# ASR6601 register map
Vendor: ASR Microelectronics; Series: ASR6601; File version: 1
CPU: CM4 r0p1, little endian, no MPU, FPU, 3 interrupt priority bits
Registers are 32-bit, read-write, reset 0x0 unless marked. A register's access mark holds for its fields unless they carry their own. Offsets are from the block's base; [hi:lo] are bit positions; {n}, {i} and the like mark numbered series.

## RCC — Reset and clock control
Base 0x40000000
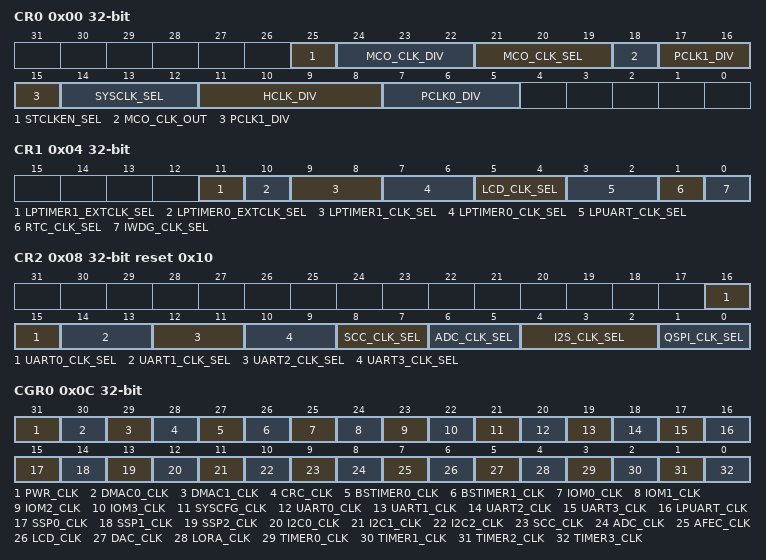
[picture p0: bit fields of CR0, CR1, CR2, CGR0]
0x00 CR0 — Clock control register 0
  [25] STCLKEN_SEL — SYSTICK clock source selection
    0=XO32K (XO32K is SYSTICK clock source); 1=RCO32K (RCO32K is SYSTICK clock source)
  [24:22] MCO_CLK_DIV — MCO clock source prescaler
    0=MCO clock source is used directly; 4=MCO clock source is divided by 2; 5=MCO clock source is divided by 4; 6=MCO clock source is divided by 8; 7=MCO clock source is divided by 16
  [21:19] MCO_CLK_SEL — MCO clock source selection
    0=RCO32K (RCO32K is MCO clock source); 1=XO32K (XO32K is MCO clock source); 2=RCO4M (RCO4M is MCO clock source); 3=XO24M (XO24M is MCO clock source); 4=XO32M (XO32M is MCO clock source); 5=RCO48M (RCO48M is MCO clock source); 6=PLL (PLL is MCO clock source); 7=SYSCLCK (SYSCLCK is MCO clock source)
  [18] MCO_CLK_OUT — MCO clock output
    0=DIS (MCO clock output disable); 1=EN (MCO clock output enable)
  [17:15] PCLK1_DIV — PCLK1 clock source prescaler
    0=PCLK1 clock source is used directly; 1=PCLK1 clock source is divided by 2; 2=PCLK1 clock source is divided by 4; 3=PCLK1 clock source is divided by 8; 4=PCLK1 clock source is divided by 16
  [14:12] SYSCLK_SEL — SYSCLK clock source selection
    0=RCO48M_DIV2 (RCO48M / 2 is SYSCLK clock source); 1=RCO32K (RCO32K is SYSCLK clock source); 2=XO32K (XO32K is SYSCLK clock source); 3=PLL (PLL is SYSCLK clock source); 4=XO24M (XO24M is SYSCLK clock source); 5=XO32M (XO32M is SYSCLK clock source); 6=RCO4M (RCO4M is SYSCLK clock source); 7=RCO48M (RCO48M is SYSCLK clock source)
  [11:8] HCLK_DIV — HCLK clock source prescaler
    0=HCLK clock source is used directly; 1=HCLK clock source is divided by 2; 2=HCLK clock source is divided by 4; 3=HCLK clock source is divided by 8; 4=HCLK clock source is divided by 16; 5=HCLK clock source is divided by 32; 6=HCLK clock source is divided by 64; 7=HCLK clock source is divided by 128; 8=HCLK clock source is divided by 256; 9=HCLK clock source is divided by 512
  [7:5] PCLK0_DIV — PCLK0 clock source prescaler
    0=PCLK0 clock source is used directly; 1=PCLK0 clock source is divided by 2; 2=PCLK0 clock source is divided by 4; 3=PCLK0 clock source is divided by 8; 4=PCLK0 clock source is divided by 16
0x04 CR1 — Clock control register 1
  [11] LPTIMER1_EXTCLK_SEL — LPTIMER1 external clock source enable
    0=DIS (LPTIMER1 external clock source disable); 1=EN (LPTIMER1 external clock source enable)
  [10] LPTIMER0_EXTCLK_SEL — LPTIMER0 external clock source enable
    0=DIS (LPTIMER0 external clock source disable); 1=EN (LPTIMER0 external clock source enable)
  [9:8] LPTIMER1_CLK_SEL — LPTIMER1 clock source selection
    0=PCLK0 (PCLK0 is LPTIMER1 clock source); 1=RCO4M (RCO4M is LPTIMER1 clock source); 2=XO32K (XO32K is LPTIMER1 clock source); 3=RCO32K (RCO32K is LPTIMER1 clock source)
  [7:6] LPTIMER0_CLK_SEL — LPTIMER0 clock source selection
    0=PCLK0 (PCLK0 is LPTIMER0 clock source); 1=RCO4M (RCO4M is LPTIMER0 clock source); 2=XO32K (XO32K is LPTIMER0 clock source); 3=RCO32K (RCO32K is LPTIMER0 clock source)
  [5:4] LCD_CLK_SEL — LCD clock source selection
    0=XO32K (XO32K is LCD clock source); 1=RCO32K (RCO32K is LCD clock source); 2=RCO4M (RCO4M is LCD clock source)
  [3:2] LPUART_CLK_SEL — LPUART clock source selection
    0=XO32K (XO32K is LPUART clock source); 1=RCO32K (RCO32K is LPUART clock source); 2=RCO4M (RCO4M is LPUART clock source)
  [1] RTC_CLK_SEL — RTC clock source selection
    0=XO32K (XO32K is RTC clock source); 1=RCO32K (RCO32K is RTC clock source)
  [0] IWDG_CLK_SEL — IWDG clock source selection
    0=XO32K (XO32K is IWDG clock source); 1=RCO32K (RCO32K is IWDG clock source)
0x08 CR2 reset 0x10 — Clock control register 2
  [16:15] UART0_CLK_SEL — UART0 clock source selection
    0=PCLK0 (PCLK0 is UART0 clock source); 1=RCO4M (RCO4M is UART0 clock source); 2=XO32K (XO32K is UART0 clock source); 3=XO24M (XO24M is UART0 clock source)
  [14:13] UART1_CLK_SEL — UART1 clock source selection
    0=PCLK0 (PCLK0 is UART1 clock source); 1=RCO4M (RCO4M is UART1 clock source); 2=XO32K (XO32K is UART1 clock source); 3=XO24M (XO24M is UART1 clock source)
  [12:11] UART2_CLK_SEL — UART2 clock source selection
    0=PCLK1 (PCLK1 is UART2 clock source); 1=RCO4M (RCO4M is UART2 clock source); 2=XO32K (XO32K is UART2 clock source); 3=XO24M (XO24M is UART2 clock source)
  [10:9] UART3_CLK_SEL — UART3 clock source selection
    0=PCLK1 (PCLK1 is UART3 clock source); 1=RCO4M (RCO4M is UART3 clock source); 2=XO32K (XO32K is UART3 clock source); 3=XO24M (XO24M is UART3 clock source)
  [8:7] SCC_CLK_SEL — SCC clock source selection
    0=PCLK1 (PCLK1 is SCC clock source); 1=SYSCLK (SYSCLK is SCC clock source); 2=PLL (PLL is SCC clock source); 3=EXT (EXT is SCC clock source)
  [6:5] ADC_CLK_SEL — ADC clock source selection
    0=PCLK1 (PCLK1 is ADC clock source); 1=SYSCLK (SYSCLK is ADC clock source); 2=PLL (PLL is ADC clock source); 3=RCO48M (RCO48M is ADC clock source)
  [4:2] I2S_CLK_SEL — I2S clock source selection
    0=PCLK0 (PCLK0 is I2S clock source); 1=XO24M (XO24M is I2S clock source); 2=PLL (PLL is I2S clock source); 3=XO32M (XO32M is I2S clock source); 4=EXT (EXT is I2S clock source)
  [1:0] QSPI_CLK_SEL — QSPI clock source selection
    0=HCLK (HCLK is QSPI clock source); 1=SYSCLK (SYSCLK is QSPI clock source); 2=PLL (PLL is QSPI clock source)
0x0C CGR0 — Clock generation register 0
  [31] PWR_CLK — PWR clock
    0=DIS (PWR clock disable); 1=EN (PWR clock enable)
  [30] DMAC0_CLK — DMAC0 clock
    0=DIS (DMAC0 clock disable); 1=EN (DMAC0 clock enable)
  [29] DMAC1_CLK — DMAC1 clock
    0=DIS (DMAC1 clock disable); 1=EN (DMAC1 clock enable)
  [28] CRC_CLK — CRC clock
    0=DIS (CRC clock disable); 1=EN (CRC clock enable)
  [27] BSTIMER0_CLK — BSTIMER0 clock
    0=DIS (BSTIMER0 clock disable); 1=EN (BSTIMER0 clock enable)
  [26] BSTIMER1_CLK — BSTIMER1 clock
    0=DIS (BSTIMER1 clock disable); 1=EN (BSTIMER1 clock enable)
  [25-n] IOM{n}_CLK (n=0..3) — IOM{n} clock
    0=DIS (IOM{n} clock disable); 1=EN (IOM{n} clock enable)
  [21] SYSCFG_CLK — SYSCFG clock
    0=DIS (SYSCFG clock disable); 1=EN (SYSCFG clock enable)
  [20-n] UART{n}_CLK (n=0..3) — UART{n} clock
    0=DIS (UART{n} clock disable); 1=EN (UART{n} clock enable)
  [16] LPUART_CLK — LPUART clock
    0=DIS (LPUART clock disable); 1=EN (LPUART clock enable)
  [15] SSP0_CLK — SSP0 clock
    0=DIS (SSP0 clock disable); 1=EN (SSP0 clock enable)
  [14] SSP1_CLK — SSP1 clock
    0=DIS (SSP1 clock disable); 1=EN (SSP1 clock enable)
  [13] SSP2_CLK — SSP2 clock
    0=DIS (SSP2 clock disable); 1=EN (SSP2 clock enable)
  [12] I2C0_CLK — I2C0 clock
    0=DIS (I2C0 clock disable); 1=EN (I2C0 clock enable)
  [11] I2C1_CLK — I2C1 clock
    0=DIS (I2C1 clock disable); 1=EN (I2C1 clock enable)
  [10] I2C2_CLK — I2C2 clock
    0=DIS (I2C2 clock disable); 1=EN (I2C2 clock enable)
  [9] SCC_CLK — SCC clock
    0=DIS (SCC clock disable); 1=EN (SCC clock enable)
  [8] ADC_CLK — ADC clock
    0=DIS (ADC clock disable); 1=EN (ADC clock enable)
  [7] AFEC_CLK — AFEC clock
    0=DIS (AFEC clock disable); 1=EN (AFEC clock enable)
  [6] LCD_CLK — LCD clock
    0=DIS (LCD clock disable); 1=EN (LCD clock enable)
  [5] DAC_CLK — DAC clock
    0=DIS (DAC clock disable); 1=EN (DAC clock enable)
  [4] LORA_CLK — LORA clock
    0=DIS (LORA clock disable); 1=EN (LORA clock enable)
  [3-n] TIMER{n}_CLK (n=0..3) — TIMER{n} clock
    0=DIS (TIMER{n} clock disable); 1=EN (TIMER{n} clock enable)
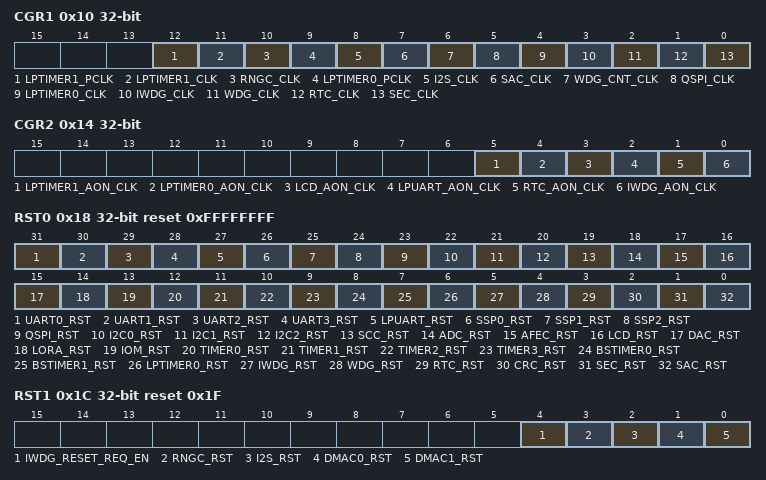
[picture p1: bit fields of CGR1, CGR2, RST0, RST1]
0x10 CGR1 — Clock generation register 1
  [12] LPTIMER1_PCLK — LPTIMER1 PCLK clock
    0=DIS (LPTIMER1 PCLK clock disable); 1=EN (LPTIMER1 PCLK clock enable)
  [11] LPTIMER1_CLK — LPTIMER1 clock
    0=DIS (LPTIMER1 clock disable); 1=EN (LPTIMER1 clock enable)
  [10] RNGC_CLK — RNGC clock
    0=DIS (RNGC clock disable); 1=EN (RNGC clock enable)
  [9] LPTIMER0_PCLK — LPTIMER0 PCLK clock
    0=DIS (LPTIMER0 PCLK clock disable); 1=EN (LPTIMER0 PCLK clock enable)
  [8] I2S_CLK — I2S clock
    0=DIS (I2S clock disable); 1=EN (I2S clock enable)
  [7] SAC_CLK — SAC clock
    0=DIS (SAC clock disable); 1=EN (SAC clock enable)
  [6] WDG_CNT_CLK — WDG_CNT clock
    0=DIS (WDG_CNT clock disable); 1=EN (WDG_CNT clock enable)
  [5] QSPI_CLK — QSPI clock
    0=DIS (QSPI clock disable); 1=EN (QSPI clock enable)
  [4] LPTIMER0_CLK — LPTIMER0 clock
    0=DIS (LPTIMER0 clock disable); 1=EN (LPTIMER0 clock enable)
  [3] IWDG_CLK — IWDG clock
    0=DIS (IWDG clock disable); 1=EN (IWDG clock enable)
  [2] WDG_CLK — WDG clock
    0=DIS (WDG clock disable); 1=EN (WDG clock enable)
  [1] RTC_CLK — RTC clock
    0=DIS (RTC clock disable); 1=EN (RTC clock enable)
  [0] SEC_CLK — SEC clock
    0=DIS (SEC clock disable); 1=EN (SEC clock enable)
0x14 CGR2 — Clock generation register 2
  [5] LPTIMER1_AON_CLK — LPTIMER1 AON clock
    0=DIS (LPTIMER1 AON clock disable); 1=EN (LPTIMER1 AON clock enable)
  [4] LPTIMER0_AON_CLK — LPTIMER0 AON clock
    0=DIS (LPTIMER0 AON clock disable); 1=EN (LPTIMER0 AON clock enable)
  [3] LCD_AON_CLK — LCD AON clock
    0=DIS (LCD AON clock disable); 1=EN (LCD AON clock enable)
  [2] LPUART_AON_CLK — LPUART AON clock
    0=DIS (LPUART AON clock disable); 1=EN (LPUART AON clock enable)
  [1] RTC_AON_CLK — RTC AON clock
    0=DIS (RTC AON clock disable); 1=EN (RTC AON clock enable)
  [0] IWDG_AON_CLK — IWDG AON clock
    0=DIS (IWDG AON clock disable); 1=EN (IWDG AON clock enable)
0x18 RST0 reset 0xFFFFFFFF — Reset register 0
  [all] fields
    0=CLR_FLAG (Reset state); 1=SET_FLAG (Working state)
  [31-n] UART{n}_RST (n=0..3) — UART{n} reset
  [27] LPUART_RST — LPUART reset
  [26] SSP0_RST — SSP0 reset
  [25] SSP1_RST — SSP1 reset
  [24] SSP2_RST — SSP2 reset
  [23] QSPI_RST — QSPI reset
  [22] I2C0_RST — I2C0 reset
  [21] I2C1_RST — I2C1 reset
  [20] I2C2_RST — I2C2 reset
  [19] SCC_RST — SCC reset
  [18] ADC_RST — ADC reset
  [17] AFEC_RST — AFEC reset
  [16] LCD_RST — LCD reset
  [15] DAC_RST — DAC reset
  [14] LORA_RST — LORA reset
  [13] IOM_RST — IOM reset
  [12-n] TIMER{n}_RST (n=0..3) — TIMER{n} reset
  [8] BSTIMER0_RST — BSTIMER0 reset
  [7] BSTIMER1_RST — BSTIMER1 reset
  [6] LPTIMER0_RST — LPTIMER0 reset
  [5] IWDG_RST — IWDG reset
  [4] WDG_RST — WDG reset
  [3] RTC_RST — RTC reset
  [2] CRC_RST — CRC reset
  [1] SEC_RST — SEC reset
  [0] SAC_RST — SAC reset
0x1C RST1 reset 0x1F — Reset register 1
  [all] fields
    0=CLR_FLAG (Reset state); 1=SET_FLAG (Working state)
  [4] IWDG_RESET_REQ_EN — LPTIMER1 reset
  [3] RNGC_RST — RNGC reset
  [2] I2S_RST — I2S reset
  [1] DMAC0_RST — DMAC0 reset
  [0] DMAC1_RST — DMAC1 reset
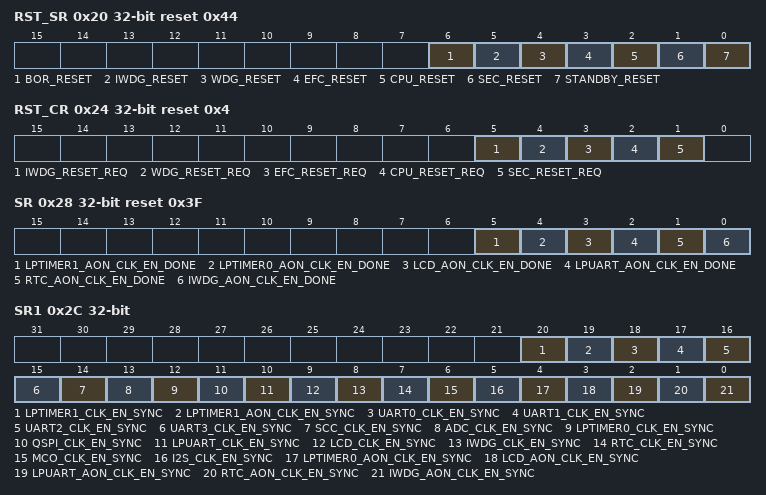
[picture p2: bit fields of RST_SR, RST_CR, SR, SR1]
0x20 RST_SR reset 0x44 — Reset status register
  [all] fields
    0=CLR_FLAG (Not detected); 1=SET_FLAG (Detected)
  [6] BOR_RESET — Reset from BOR
  [5] IWDG_RESET — Reset from IWDG
  [4] WDG_RESET — Reset from WDG
  [3] EFC_RESET — Reset from EFC
  [2] CPU_RESET — Reset from CPU
  [1] SEC_RESET — Reset from SEC
  [0] STANDBY_RESET — Reset from STANDBY
0x24 RST_CR reset 0x4 — Reset control register
  [5] IWDG_RESET_REQ — IWDG reset request
    0=DIS (IWDG reset request disable); 1=SET_FLAG (IWDG reset request enable)
  [4] WDG_RESET_REQ — WDG reset request
    0=DIS (WDG reset request disable); 1=SET_FLAG (WDG reset request enable)
  [3] EFC_RESET_REQ — EFC reset request
    0=DIS (EFC reset request disable); 1=SET_FLAG (EFC reset request enable)
  [2] CPU_RESET_REQ — CPU reset request
    0=DIS (CPU reset request disable); 1=SET_FLAG (CPU reset request enable)
  [1] SEC_RESET_REQ — SEC reset request
    0=DIS (SEC reset request disable); 1=SET_FLAG (SEC reset request enable)
0x28 SR ro reset 0x3F — Status register
  [all] fields
    0=CLR_FLAG (Not done); 1=SET_FLAG (Done)
  [5] LPTIMER1_AON_CLK_EN_DONE
  [4] LPTIMER0_AON_CLK_EN_DONE
  [3] LCD_AON_CLK_EN_DONE
  [2] LPUART_AON_CLK_EN_DONE
  [1] RTC_AON_CLK_EN_DONE
  [0] IWDG_AON_CLK_EN_DONE
0x2C SR1 ro — Status register 1
  [20] LPTIMER1_CLK_EN_SYNC
    0=CLR_FLAG (LPTIMER1 clock not synchronized); 1=SET_FLAG (LPTIMER1 clock synchronized)
  [19] LPTIMER1_AON_CLK_EN_SYNC
    0=CLR_FLAG (Not synchronized); 1=SET_FLAG (Synchronized)
  [18-n] UART{n}_CLK_EN_SYNC (n=0..3)
    0=CLR_FLAG (Not synchronized); 1=SET_FLAG (Synchronized)
  [14] SCC_CLK_EN_SYNC
    0=CLR_FLAG (Not synchronized); 1=SET_FLAG (Synchronized)
  [13] ADC_CLK_EN_SYNC
    0=CLR_FLAG (Not synchronized); 1=SET_FLAG (Synchronized)
  [12] LPTIMER0_CLK_EN_SYNC
    0=CLR_FLAG (Not synchronized); 1=SET_FLAG (Synchronized)
  [11] QSPI_CLK_EN_SYNC
    0=CLR_FLAG (Not synchronized); 1=SET_FLAG (Synchronized)
  [10] LPUART_CLK_EN_SYNC
    0=CLR_FLAG (Not synchronized); 1=SET_FLAG (Synchronized)
  [9] LCD_CLK_EN_SYNC
    0=CLR_FLAG (Not synchronized); 1=SET_FLAG (Synchronized)
  [8] IWDG_CLK_EN_SYNC
    0=CLR_FLAG (Not synchronized); 1=SET_FLAG (Synchronized)
  [7] RTC_CLK_EN_SYNC
    0=CLR_FLAG (Not synchronized); 1=SET_FLAG (Synchronized)
  [6] MCO_CLK_EN_SYNC
    0=CLR_FLAG (Not synchronized); 1=SET_FLAG (Synchronized)
  [5] I2S_CLK_EN_SYNC
    0=CLR_FLAG (Not synchronized); 1=SET_FLAG (Synchronized)
  [4] LPTIMER0_AON_CLK_EN_SYNC
    0=CLR_FLAG (Not synchronized); 1=SET_FLAG (Synchronized)
  [3] LCD_AON_CLK_EN_SYNC
    0=CLR_FLAG (Not synchronized); 1=SET_FLAG (Synchronized)
  [2] LPUART_AON_CLK_EN_SYNC
    0=CLR_FLAG (Not synchronized); 1=SET_FLAG (Synchronized)
  [1] RTC_AON_CLK_EN_SYNC
    0=CLR_FLAG (Not synchronized); 1=SET_FLAG (Synchronized)
  [0] IWDG_AON_CLK_EN_SYNC
    0=CLR_FLAG (Not synchronized); 1=SET_FLAG (Synchronized)
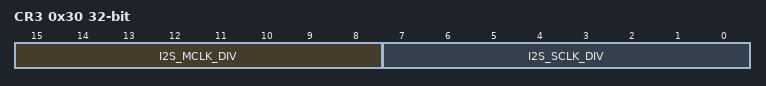
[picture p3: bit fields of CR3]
0x30 CR3 — Clock control register 3
  [15:8] I2S_MCLK_DIV, [7:0] I2S_SCLK_DIV
